# dm64lc_cslr_hecc_ctrl register map
Vendor: Texas Instruments
Peripheral module from a debugger description file.
Registers are 32-bit, access not given, reset 0x0 unless marked. A register's access mark holds for its fields unless they carry their own. Offsets are as the file gives them; lines under a group give offsets from that group; [hi:lo] are bit positions; {n}, {i} and the like mark numbered series; 'fields as' and 'values as' point back to an identical list; <NAME> marks a mode.

## HECC — This module provides an interface to program the High End CAN Controller (HECC) registers.
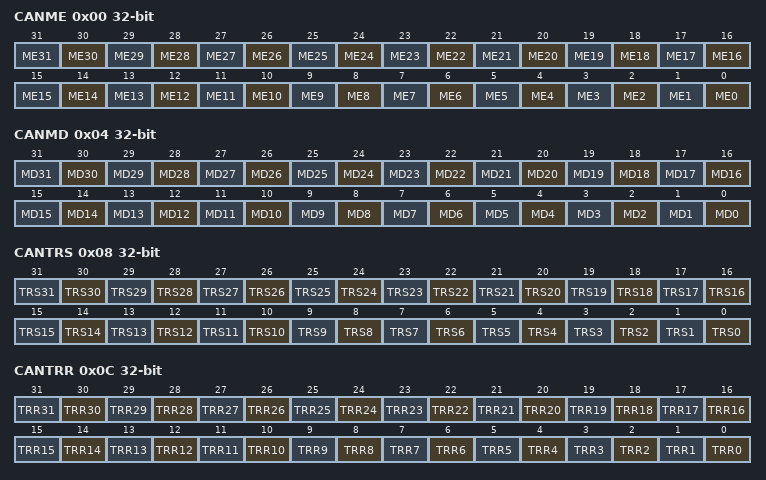
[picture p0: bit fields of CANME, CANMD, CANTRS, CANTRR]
0x00 CANME rw — Mailbox Enable Register. The mailbox must be disabled before writing to the contents of any identifier field. If the corresponding bit in CANME is set, the write access to the identifier of a message object is discarded.
  [n] ME{n} (n=0..31) — Mailbox enable register. After power-up, all bits in CANME are cleared. Disabled mailboxes may be used as additional memory for the CPU. 0 The mailbox is disabled. 1 The mailbox is enabled in the CAN module.
0x04 CANMD rw — Mailbox Direction Register
  [n] MD{n} (n=0..31) — Mailbox direction. After power-up, all bits in CANMD are cleared. 0 The mailbox is defined as a transmit mailbox. 1 The mailbox is defined as a receive mailbox.
0x08 CANTRS rw — Transmit Request Set Register
  [n] TRS{n} (n=0..31) — Transmit request set. A successful transmission initiates a GMIF0/GMIF1 interrupt (bit 15 in CANGIF0/CANGIF1) if enabled. After power-up, all bits in CANTRS are cleared. 0 No operation occurs. 1 If the corresponding message object is configured as a transmit mailbox or remote request mailbox, the data or remote message of this mailbox will be transmitted.
0x0C CANTRR rw — Transmit Request Reset Register
  [n] TRR{n} (n=0..31) — Transmit request reset. A successful transmission initiates a GMIF0/GMIF1 interrupt (bit 15 in CANGIF0/CANGIF1) if enabled.
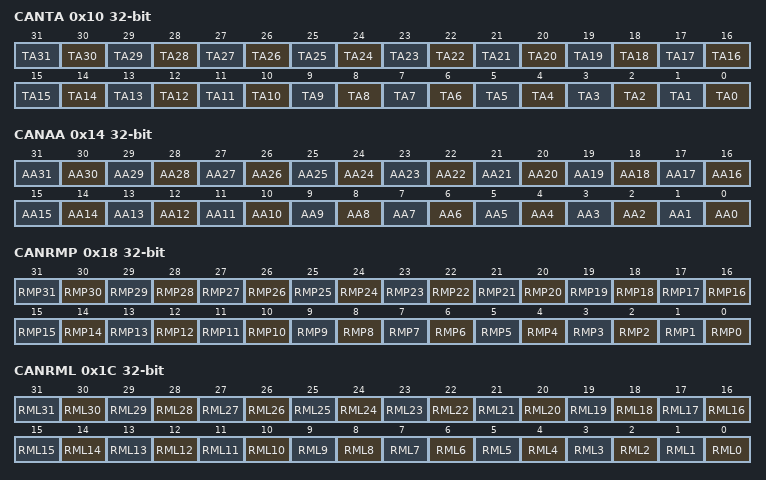
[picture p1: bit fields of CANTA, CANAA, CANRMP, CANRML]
0x10 CANTA rw — Transmission Acknowledge Register
  [n] TA{n} (n=0..31) — Transmit acknowledge.
0x14 CANAA rw — Abort Acknowledge Register
  [n] AA{n} (n=0..31) — Transmission abort acknowledge.
0x18 CANRMP rw — Receive Message Pending Register
  [n] RMP{n} (n=0..31) — Receive message pending. 0 Mailbox n does not contain a message. 1 Mailbox n contains a received message.
0x1C CANRML rw — Receive Message Lost Register
  [n] RML{n} (n=0..31) — Receive message lost. 0 No message was lost. 1 An old unread message has been overwritten by a new message.
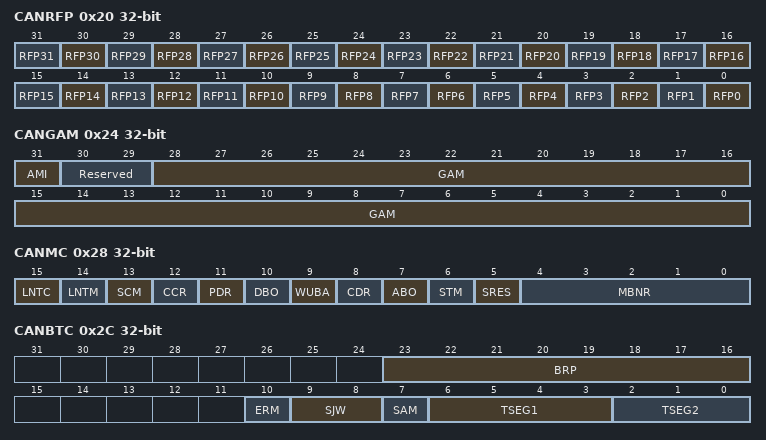
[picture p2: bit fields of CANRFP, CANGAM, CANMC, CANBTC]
0x20 CANRFP rw — Remote Frame Pending Register
  [n] RFP{n} (n=0..31) — Remote frame pending. 0 No remote frame request was received. 1 A remote frame request was received by the module.
0x24 CANGAM — Global acceptance mask in SCC mode. Reserved in HECC mode.
  [31] AMI rw — Acceptance mask identifier extension. 0 The identifier extension bit stored in the mailbox determines which messages shall be received. 1 Standard and extended frames can be received. In the case of an extended frame, all 29 bits of the identifier are stored in the mailbox and all 29 GAM bits are used for the filter. In the case of a standard frame, only the first 11 bits (bits 28-18) of the identifier and the GAM bits are used.
  [30:29] Reserved — (access N)
  [28:0] GAM rw — Global acceptance mask. These bits allow any identifier bits of an incoming message to be masked.
0x28 CANMC — Master Control Register(There is a reserve space at 0x12)
  [15] LNTC rw — Local network time clear. HECC only; reserved in the SCC. This bit is protected in user mode. 0 The local network time register (CANLNT) is not reset. 1 The local network time register (CANLNT) is reset to 0 after a successful transmission or reception of mailbox 16.
  [14] LNTM rw — Local network time MSB clear. HECC only; reserved in the SCC. This bit is protected in user mode. 0 The local network time register (CANLNT) is not changed. 1 The most-significant bit (MSB) of the local network time register (CANLNT) is reset to 0. The LNTM bit is reset after one clock cycle by the internal logic.
  [13] SCM rw — SCC-compatibility mode. HECC only; reserved in the SCC. This bit is protected in user mode. The HECC behaves like the SCC and only mailboxes 15-0 are used. See the SCC specification to operate the HECC in this mode. Since this mode is selected by default, all software developed for the SCC runs without any change to the HECC module. 0 The HECC is in SCC-compatibility mode. 1 The HECC is in normal mode.
  [12] CCR rw — Change configuration request. This bit is protected in user mode. 0 The CPU requests normal operation. This can only be done after the bit-timing configuration register (CANBTC) is set to the allowed values. 1 The CPU requests write access to the bit-timing configuration register (CANBTC) and the acceptance mask registers (CANGAM, LAM(0), and LAM(3)) of the SCC. After setting this bit, the CPU must wait until the CCE bit in the error and status register (CANES) is set to 1 before proceeding to CANBTC. This could also mean that the CAN module is in bus-off state (the BO bit in CANES). When the CCR bit is set, no new transmit requests can be issued.
  [11] PDR rw — Power-down-mode request. This bit is protected in user mode. 0 The CAN module power-down mode is not requested (normal operation). 1 The CAN module power-down mode is requested.
  [10] DBO rw — Data byte order. This bit selects the byte order of the message data field.This bit is protected in user mode. 0 The data is received or transmitted most-significant byte first. 1 The data is received or transmitted least-significant byte first.
  [9] WUBA rw — Wake up on bus activity. This bit is protected in user mode. 0 The module leaves the power-down mode only after writing a 0 to the PDR bit. 1 The module leaves the power-down mode after detecting any bus activity.
  [8] CDR rw — Change data field request. This bit allows fast data message updates. 0 The CPU requests normal operation. 1 The CPU requests write access to the data field of the mailbox specified by the MBNR field. The CPU must clear the CDR bit after accessing the mailbox. The CAN module does not transmit that mailbox content while the CDR bit is set. This bit is checked by the state machine before and after it reads the data from the mailbox to store it in the transmit buffer. Update data with CDR mechanism.
  [7] ABO rw — Auto bus on. This bit is protected in user mode. 0 The CCR bit is set when the bus-off state is detected. The CCR bit should be cleared before resuming any CAN communication. The bus-off state is exited after 128 x 11 recessive bits. 1 After the bus-off state, the CAN module goes back automatically into the bus-on state after 128 x 11 recessive bits.
  [6] STM rw — Self-test mode This bit is protected in user mode. 0 The module is in normal mode. 1 The module is in self-test mode. In this mode, the CAN module generates its own acknowledge (ACK) signal, thus enabling operation without a bus connected to the module. The message is not sent, but is read back and stored in the appropriate mailbox.
  [5] SRES rw — Software reset. This bit can only be written to and is always read as 0. 0 No effect occurs. 1 A write access to this register causes a software reset of the module, that is, all parameters, except the following bits, are reset to their default values. BRP, ERM, SJW, SAM, TSEG1, and TSEG2 in CANBTC LNTC, LNTM, SCM, CCR, PDR, DBO, WUBA, ABO, and STM in CANMC TXFUNC in CANTIOC RXFUNC in CANRIOC The mailbox contents and the error counters are not modified. Pending and ongoing transmissions are canceled without disturbing the communication.
  [4:0] MBNR rw — Mailbox number. The MBNR bit 4 is for the HECC only and is reserved in the SCC. This is the number of the mailbox for which the CPU requests a write access to the data field. This field is used in conjunction with the CDR bit.
0x2C CANBTC — Bit Timing Configuration Register
  [23:16] BRP rw — Time quantum prescaler. Specifies the duration of a time quantum (TQ) in CAN module system clock units. The length of one TQ is defined by: TQ = BRP/VBUSP CLK where VBUSP CLK is the frequency of the CAN module system clock and BRP is the binary value of (BRP + 1), calculated as follows: BRP = 1 + BRP.0 + (2 x BRP.1) + (4 x BRP.2) + (8 x BRP.3) + (16 x BRP.4) + (32 x BRP.5) + (64 x BRP.6) + (128 x BRP.7) The value programmed into the CANBTC register must be decremented by 1, because of the 8-bit size of the binary BRP value (BRP[7:0]).
  [10] ERM rw — Edge resynchronization mode. This bit selects the synchronization mode with the receive data stream on the CAN bus. 0 The CAN modulel resynchronizes on the falling edge only. 1 The CAN module resynchronizes on both rising and falling edges.
  [9:8] SJW rw — Synchronization jump width. Indicates how many units of TQ a bit is allowed to be lengthened or shortened when resynchronizing with the receive data stream on the CAN bus.The synchronization is performed either with the falling edge (ERM = 0) or with both edges (ERM = 1) of the bus signal. The synchronization jump width, SJW, is calculated as follows: SJW = 1 + SJW.0 + (2 x SJW.1) SJW is programmable from 14 TQ. The maximum value of SJW is determined by the minimum value of TSEG2CALC or 4TQ.
  [7] SAM rw — Sample point setting. Sets the number of samples used by the CAN module to determine the actual level of the CAN bus. When the SAM bit is set, the level determined by the CAN bus corresponds to the result from the majority decision of the last three values. The sample points are at the sample point and twice before with a distance of 1/2 TQ. 0 The CAN module samples only once at the sampling point. 1 The CAN module samples three times and makes a majority decision. The triple sample mode shall be selected only for bit rate prescale values greater than 4 (BRPCALC > 4).
  [6:3] TSEG1 rw — Time segment 1. Specifies the length of the TSEG1 segment in TQ units. The value of TSEG1 is calculated as follows: TSEG1 = 1 + TSEG1.0 + (2 x TSEG1.1) + (4 x TSEG1.2) + (8 x TSEG1.3)
  [2:0] TSEG2 rw — Time segment 2. Specifies the length of the PHASE_SEG2 segment in TQ units and is calculated as follow: TSEG2 = 1 + TSEG2.0 + (2 x TSEG2.1) + (4 x TSEG2.2)
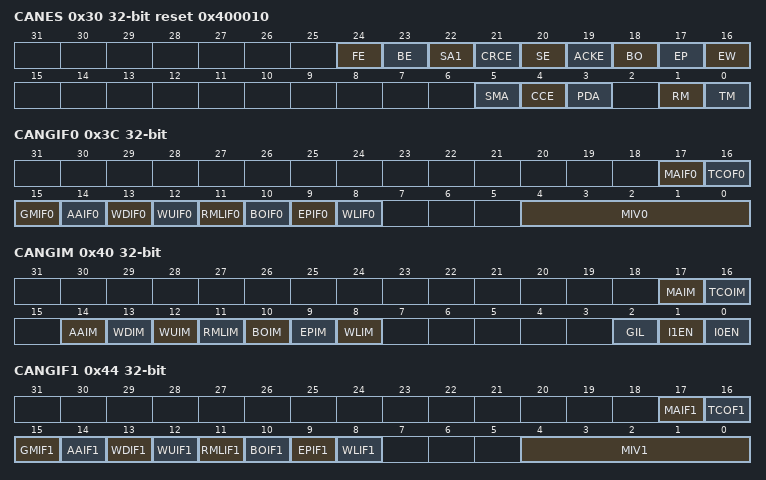
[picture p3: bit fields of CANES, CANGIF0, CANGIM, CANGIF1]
0x30 CANES reset 0x400010 — Error and Status Register
  [24] FE rw — Form error
  [23] BE rw — Bit error
  [22] SA1 rw — Stuck at Dominant error
  [21] CRCE rw — CRC error
  [20] SE rw — Stuff error
  [19] ACKE rw — Acknowledge error
  [18] BO rw — Bus-off error
  [17] EP rw — Error-Passive state
  [16] EW rw — Warning status
  [5] SMA rw — Suspend mode Acknowledge
  [4] CCE rw — Change Configuration Enable
  [3] PDA rw — Power-down mode Acknowledge
  [1] RM rw — Receive mode
  [0] TM rw — Transmit mode
0x34 CANTEC — Transmit Error Counter Register
  [7:0] TEC rw — Transmit Error counter
0x38 CANREC — Receive Error Counter Register
  [7:0] REC rw — Receive Error counter
0x3C CANGIF0 — Global Interrupt flag0 Register
  [17] MAIF0 rw — Message alarm flag. HECC only, reserved in the SCC. 0 No time out for the mailboxes occurred. 1 One of the mailboxes did not transmit or receive a message within the specified time frame.
  [16] TCOF0 rw — Local network time counter overflow flag. HECC only, reserved in the SCC. 0 The MSB of the local network time register (CANLNT) is 0. 1 The MSB of the local network time register (CANLNT) is 1.
  [15] GMIF0 rw — Global mailbox interrupt flag. 0 No message has been transmitted or received. 1 One of the mailboxes transmitted or received a message successfully.
  [14] AAIF0 rw — Abort-acknowledge interrupt flag
  [13] WDIF0 rw — Write-denied interrupt flag
  [12] WUIF0 rw — Wake-up interrupt flag
  [11] RMLIF0 rw — Receive message lost interrupt flag
  [10] BOIF0 rw — Bus off interrupt flag
  [9] EPIF0 rw — Error passive interrupt flag
  [8] WLIF0 rw — Warning level interrupt flag
  [4:0] MIV0 rw — Message object interrupt vector
0x40 CANGIM — Global Interrupt Mask Register
  [17] MAIM rw — Message alarm interrupt mask. HECC only, reserved in the SCC.
  [16] TCOIM rw — Local network time counter overflow interrupt mask. HECC only, reserved in the SCC.
  [14] AAIM rw — Abort-acknowledge interrupt mask
  [13] WDIM rw — Write-denied interrupt mask
  [12] WUIM rw — Wake-up interrupt mask
  [11] RMLIM rw — Receive message lost interrupt mask
  [10] BOIM rw — Bus off interrupt mask
  [9] EPIM rw — Error passive interrupt mask
  [8] WLIM rw — Warning level interrupt mask
  [2] GIL rw — Global interrupt level
  [1] I1EN rw — Interrupt 1 enable
  [0] I0EN rw — Interrupt 0 enable
0x44 CANGIF1 — Global Interrupt flag1 Register
  [17] MAIF1 rw — Message alarm flag. HECC only, reserved in the SCC. 0 No time out for the mailboxes occurred. 1 One of the mailboxes did not transmit or receive a message within the specified time frame.
  [16] TCOF1 rw — Local network time counter overflow flag. HECC only, reserved in the SCC. 0 The MSB of the local network time register (CANLNT) is 0. 1 The MSB of the local network time register (CANLNT) is 1.
  [15] GMIF1 rw — Global mailbox interrupt flag. 0 No message has been transmitted or received. 1 One of the mailboxes transmitted or received a message successfully.
  [14] AAIF1 rw — Abort-acknowledge interrupt flag
  [13] WDIF1 rw — Write-denied interrupt flag
  [12] WUIF1 rw — Wake-up interrupt flag
  [11] RMLIF1 rw — Receive message lost interrupt flag
  [10] BOIF1 rw — Bus off interrupt flag
  [9] EPIF1 rw — Error passive interrupt flag
  [8] WLIF1 rw — Warning level interrupt flag
  [4:0] MIV1 rw — Message object interrupt vector
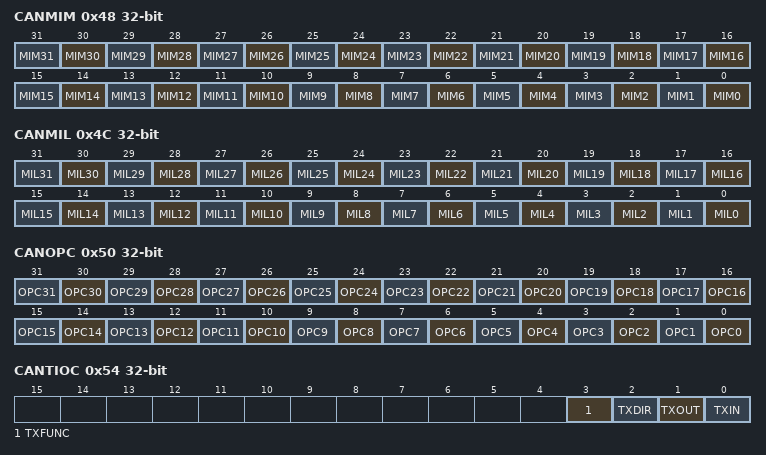
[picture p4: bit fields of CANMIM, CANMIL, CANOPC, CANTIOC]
0x48 CANMIM rw — Mailbox Interrupt Mask Register
  [n] MIM{n} (n=0..31) — Mailbox interrupt mask. Selects any mailbox interrupt to be masked individually. 0 The mailbox interrupt is disabled. 1 The mailbox interrupt is enabled. An interrupt is generated if a message has been transmitted successfully (in case of a transmit mailbox) or if a message has been received without any error (in case of a receive mailbox).
0x4C CANMIL rw — Mailbox Interrupt Level Register
  [n] MIL{n} (n=0..31) — Mailbox interrupt level. 0 The mailbox interrupt is generated on interrupt line 0 (HECC0INT/SCC0INT). 1 The mailbox interrupt is generated on interrupt line 1 (HECC1INT/SCC1INT).
0x50 CANOPC rw — Overwrite Protection Control Register
  [n] OPC{n} (n=0..31) — Overwrite protection control. 0 The old message may be overwritten by a new message. 1 An old message stored in the mailbox is protected against being over-written by a new message.
0x54 CANTIOC — TX I/O Control Register
  [3] TXFUNC rw — TX pin I/O enable flag
  [2] TXDIR rw — TX pin direction flag
  [1] TXOUT rw — TX pin output value
  [0] TXIN rw — TX pin value
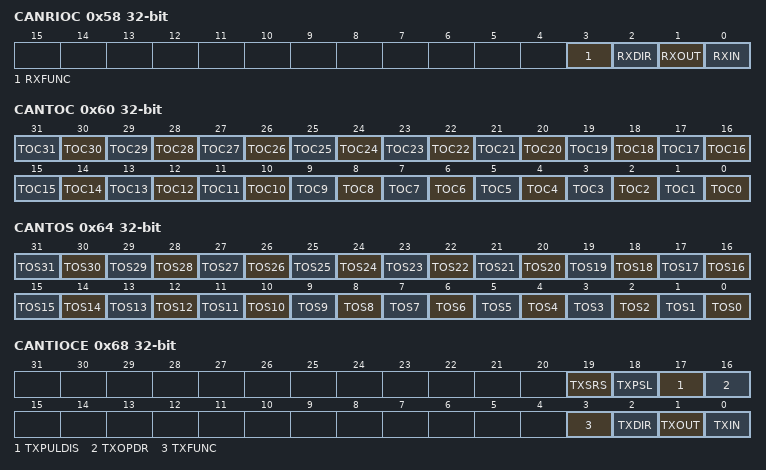
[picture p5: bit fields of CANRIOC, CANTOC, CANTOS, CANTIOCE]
0x58 CANRIOC — RX I/O Control Register
  [3] RXFUNC rw — RX pin I/O enable flag
  [2] RXDIR rw — RX pin direction flag
  [1] RXOUT rw — RX pin output value
  [0] RXIN rw — RX pin value
0x5C CANLNT rw — Local Network Time Register
  [31:0] LNT — Local network time register. The value of the local network time counter is used for the time-stamp and the time-out functions.
0x60 CANTOC rw — Time-out Control Register
  [n] TOC{n} (n=0..31) — Time-out control register. 0 The time-out function is disabled. The TOS[n] bit in the time-out status register (CANTOS) is never set. 1 The time-out function is enabled.
0x64 CANTOS rw — Time-out Status Register
  [n] TOS{n} (n=0..31) — Time-out status register. 0 No time-out occurred or the time-out function is disabled for that mailbox. 1 The value in the local network time register (CANLNT) is larger or equal to the value in the time-out register for the corresponding mailbox n and the TOC[n] bit in the time-out control register (CANTOC) is set.
0x68 CANTIOCE — Enhanced Transmit I/O Control Registers
  [19] TXSRS rw — External pin I/O slew rate select.
    0=NORMAL (The pin is at logic low (0). The normal output buffer is enabled.); 1=SLOW (The pin is at logic high (1). The slow output buffer is enabled.)
  [18] TXPSL rw — CANTX pull select.
    0=PULLDOWN (The pin is at logic low (0). Pull-down functionality is enabled.); 1=PULLUP (The pin is at logic high (1). Pull-up functionality is enabled.)
  [17] TXPULDIS rw — CANTX pull disable.
    0=ENABLE (The pin is at logic low (0). Pull functionality is enabled.); 1=DISABLE (The pin is at logic high (1). Pull functionality is disabled.)
  [16] TXOPDR rw — CANTX open drain enable.
    0=DISABLE (Open drain functionality is disabled.); 1=ENABLE (Open drain functionality is enabled.)
  [3] TXFUNC rw — External pin I/O enable flag (mirrored bit from CANTIOC). This bit is protected in user
    0=NORMAL (The CANTX pin is used as a normal I/O pin; the CAN protocol kernel (CPK) output is); 1=CANTX (The CANTX pin is used for the CAN transmit functions.)
  [2] TXDIR rw — Transmit pin direction flag (mirrored bit from CANTIOC).
    0=INPUT (The CANTX pin is used as an input pin, if CANTX is configured as an I/O pin (TXFUNC = 0)); 1=OUTPUT (The CANTX pin is used as an output pin, if CANTX is configured as an I/O pin (TXFUNC=0))
  [1] TXOUT rw — Output value for CANTX pin (mirrored bit from CANTIOC). This value is output on the CANTX is configured as an I/O pin (TXFUNC = 0) and as an output (TXDIR = 1).
  [0] TXIN rw — Input value for the CANTX pin (mirrored bit from CANTIOC) This value reflects the value on the CANTX pin
    0=LO (The pin is at logic low (0).); 1=HI (The pin is at logic high (1).)
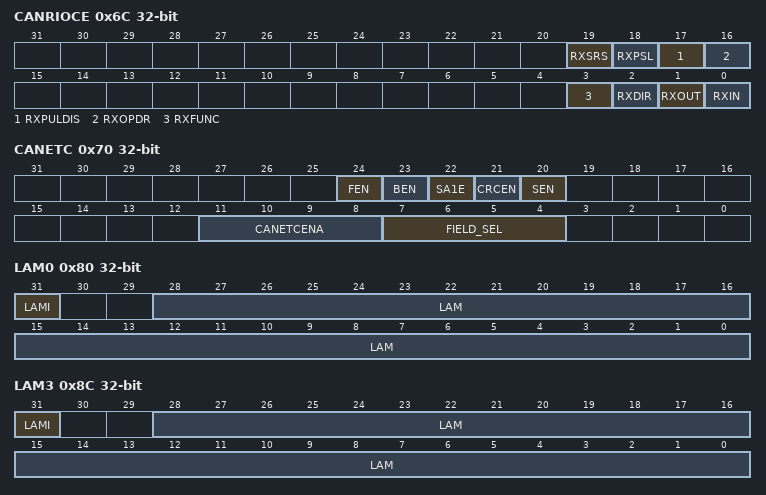
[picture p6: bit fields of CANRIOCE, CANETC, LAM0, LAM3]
0x6C CANRIOCE — Enhanced Receive I/O Control Registers
  [19] RXSRS rw — External pin I/O slew rate select.
    values as CANTIOCE.TXSRS
  [18] RXPSL rw — CANRX pull select.
    values as CANTIOCE.TXPSL
  [17] RXPULDIS rw — CANRX pull disable.
    values as CANTIOCE.TXPULDIS
  [16] RXOPDR rw — CANRX open drain enable.
    values as CANTIOCE.TXOPDR
  [3] RXFUNC rw — External pin I/O enable flag (mirrored bit from CANRIOC). This bit is protected in user
    0=NORMAL (The CANTRX pin is used as a normal I/O pin; the CAN protocol kernel (CPK) output is); 1=CANTX (The CANRX pin is used for the CAN transmit functions.)
  [2] RXDIR rw — Transmit pin direction flag (mirrored bit from CANRIOC).
    0=INPUT (The CANRX pin is used as an input pin, if CANRX is configured as an I/O pin (RXFUNC =0)); 1=OUTPUT (The CANRX pin is used as an output pin, if CANRX is configured as an I/O pin (RXFUNC =0))
  [1] RXOUT rw — Output value for CANRX pin (mirrored bit from CANRIOC). This value is output on the CANRX is configured as an I/O pin (RXFUNC = 0) and as an output (RXDIR = 1).
  [0] RXIN rw — Input value for the CANRX pin (mirrored bit from CANRIOC) This value reflects the value on the CANRX pin
    0=LO (0 The pin is at logic low (0).); 1=HI (1 The pin is at logic high (1).)
0x70 CANETC — Error Test Control Register
  [24] FEN rw — Form error enable.
    0=NOERRORGEN (No form error will be generated.); 1=ERRORGEN (A form error will be created. The bit received during the fixed format field is toggled and passed to the error checking circuitry.)
  [23] BEN rw — Bit error enable.
    0=NOERRORGEN (No bit error will be generated.); 1=ERRORGEN (A bit error will be created. The received bit is XORed with 1 and passed to the bit monitor circuitry.)
  [22] SA1E rw — Stuck at dominant error enable.
    0=NOERRORGEN (No stuck at dominant (SA1) error will be generated.); 1=ERRORGEN (The received bit is ANDed with 0 to generate a stuck at dominant (SA1) error.)
  [21] CRCEN rw — CRC error enable.
    0=NOERRORGEN (No CRC error will be generated.); 1=ERRORGEN (The CRC bits received as well as the fields used for CRC calculation are masked and passed to the CRC check circuitry.)
  [20] SEN rw — Stuff error enable.
    0=NOERRORGEN (0 No stuff error will be generated.); 1=ERRORGEN (1 The stuff bits received are toggled and passed to the error monitor circuitry.)
  [11:8] CANETCENA rw — Test register enable key.
    5=ENABLED (CANETC is enabled.)
  [7:4] FIELD_SEL rw — CAN field selects.
    0=NOFIELD (No field is selected.); 1=STDID (The STDID field is selected.); 2=DATALENGTHCODE (The DATALENGTHCODE field is selected.); 3=DATA (The DATA field is selected.); 4=CRC (The CRC field is selected.); 5=CRCDELIMIT (The CRC delimiter field is selected.); 6=ACKSLOT (The ACKSLOT field is selected.); 7=ACKDEL (The ACKDEL field is selected.); 8=ENDOFFRAME (The ENDOFFRAME field is selected.); 9=EXTID (The EXTID field is selected.)
0x80 LAM0 — SCC Local Acceptance Mask Register 0
  [31] LAMI rw — Local Acceptance Mask Identifier
  [28:0] LAM rw — Local Acceptance Mask
0x8C LAM3 — SCC Local Acceptance Mask Register 3
  fields as LAM0
